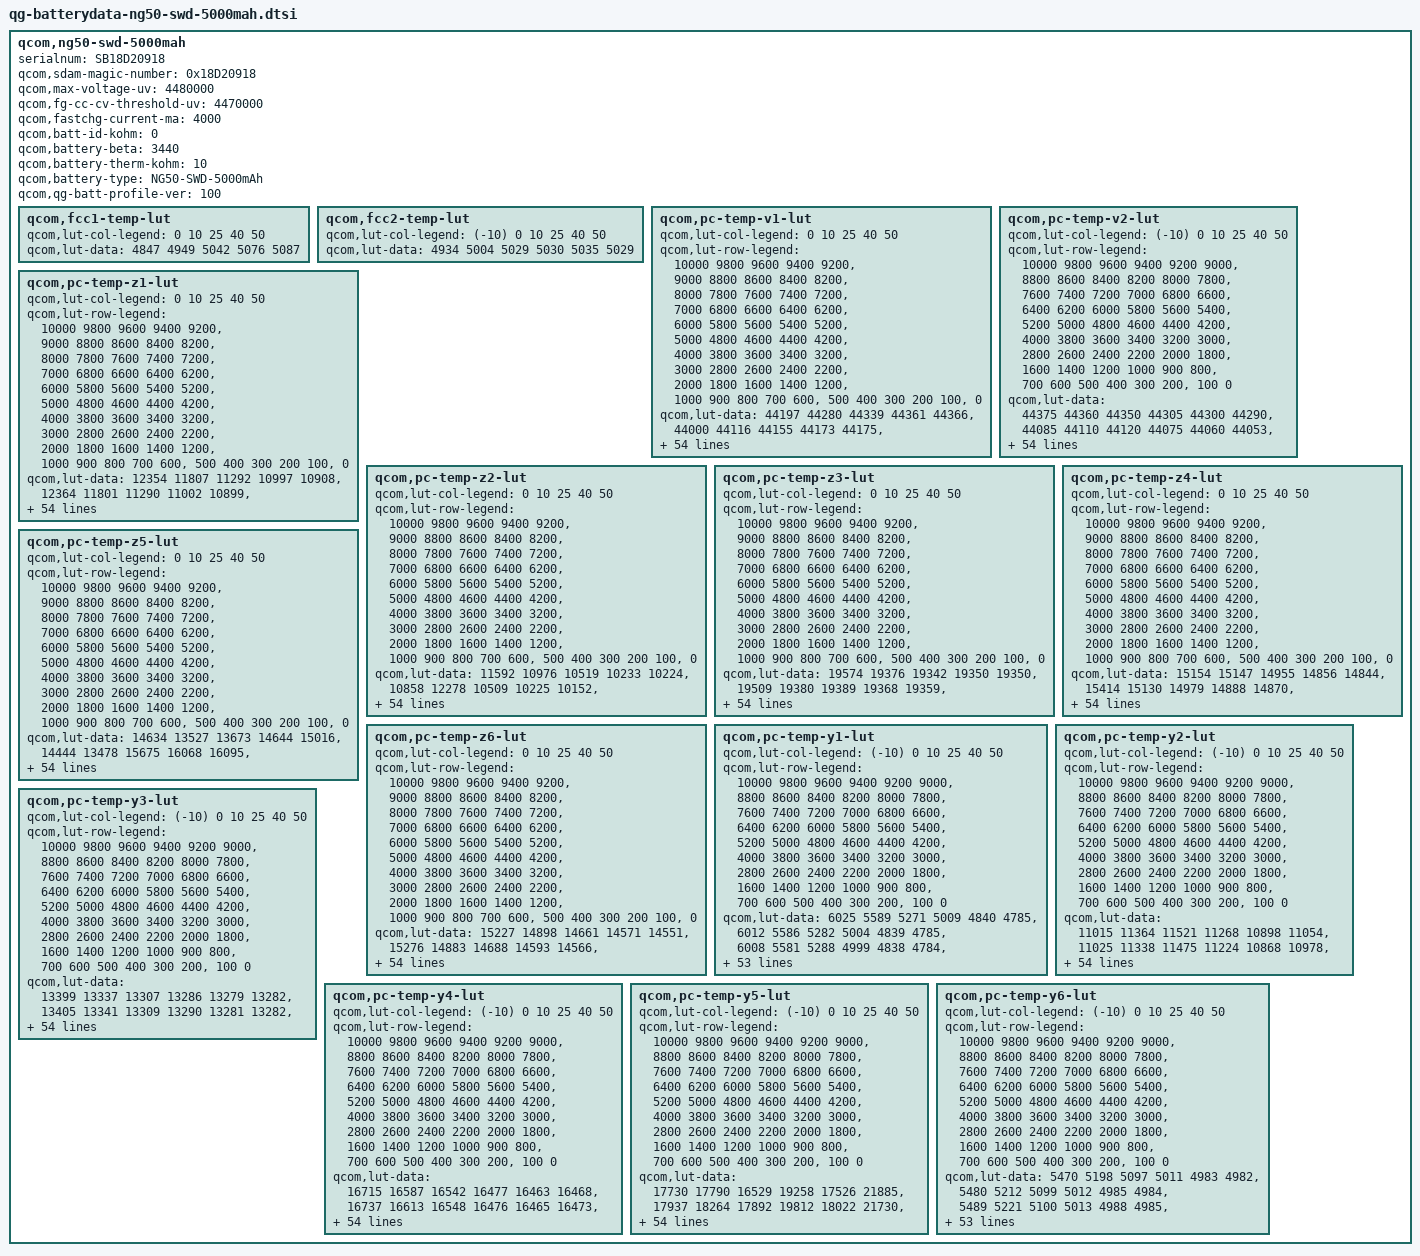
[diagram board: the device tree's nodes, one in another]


qcom,ng50-swd-5000mah {
    /* 5263913_Lenovo_Gorfu5G_Sunwoda_5000mAH_PM7250B_averaged_MasterSlave_Jul21th2021 */
    serialnum = "SB18D20918";
    qcom,sdam-magic-number = <0x18D20918>;
    qcom,max-voltage-uv = <4480000>;
    qcom,fg-cc-cv-threshold-uv = <4470000>;
    qcom,fastchg-current-ma = <4000>;
    qcom,batt-id-kohm = <0>;
    qcom,battery-beta = <3440>;
    qcom,battery-therm-kohm = <10>;
    qcom,battery-type = "NG50-SWD-5000mAh";
    qcom,qg-batt-profile-ver = <100>;

	qcom,fcc1-temp-lut {
		qcom,lut-col-legend = <0 10 25 40 50>;
		qcom,lut-data = <4847 4949 5042 5076 5087>;
	};

	qcom,fcc2-temp-lut {
		qcom,lut-col-legend = <(-10) 0 10 25 40 50>;
		qcom,lut-data = <4934 5004 5029 5030 5035 5029>;
	};

	qcom,pc-temp-v1-lut {
		qcom,lut-col-legend = <0 10 25 40 50>;
		qcom,lut-row-legend = <10000 9800 9600 9400 9200>,
			<9000 8800 8600 8400 8200>,
			<8000 7800 7600 7400 7200>,
			<7000 6800 6600 6400 6200>,
			<6000 5800 5600 5400 5200>,
			<5000 4800 4600 4400 4200>,
			<4000 3800 3600 3400 3200>,
			<3000 2800 2600 2400 2200>,
			<2000 1800 1600 1400 1200>,
			<1000 900 800 700 600>,
			<500 400 300 200 100>,
			<0>;
		qcom,lut-data = <44197 44280 44339 44361 44366>,
			<44000 44116 44155 44173 44175>,
			<43794 43931 43966 43983 43985>,
			<43581 43721 43770 43789 43792>,
			<43359 43491 43565 43585 43588>,
			<43127 43259 43351 43372 43374>,
			<42890 43025 43122 43148 43150>,
			<42650 42786 42880 42911 42917>,
			<42406 42544 42635 42668 42677>,
			<42168 42298 42392 42424 42435>,
			<41938 42058 42150 42178 42190>,
			<41714 41822 41909 41936 41949>,
			<41491 41592 41667 41696 41711>,
			<41270 41366 41432 41462 41477>,
			<41056 41147 41207 41237 41249>,
			<40851 40937 40990 41018 41025>,
			<40653 40738 40784 40805 40809>,
			<40460 40543 40588 40595 40602>,
			<40273 40356 40397 40396 40403>,
			<40083 40172 40218 40217 40219>,
			<39883 39949 40032 40041 40040>,
			<39675 39631 39792 39812 39820>,
			<39459 39336 39512 39513 39536>,
			<39211 39169 39290 39274 39293>,
			<39003 39050 39128 39133 39130>,
			<38888 38940 38992 39018 38998>,
			<38809 38835 38873 38895 38876>,
			<38732 38736 38768 38771 38764>,
			<38650 38640 38668 38660 38661>,
			<38573 38548 38570 38562 38562>,
			<38501 38464 38479 38475 38471>,
			<38432 38386 38399 38394 38389>,
			<38371 38315 38325 38319 38315>,
			<38320 38256 38258 38248 38242>,
			<38274 38205 38199 38182 38170>,
			<38234 38158 38142 38117 38097>,
			<38200 38118 38086 38051 38023>,
			<38159 38075 38030 37983 37945>,
			<38092 38008 37958 37899 37853>,
			<37997 37909 37860 37789 37734>,
			<37889 37795 37747 37664 37601>,
			<37756 37664 37623 37534 37465>,
			<37608 37518 37482 37395 37322>,
			<37437 37350 37318 37236 37157>,
			<37290 37207 37183 37115 37043>,
			<37201 37126 37098 37045 36985>,
			<37175 37097 37072 37017 36958>,
			<37150 37077 37055 36999 36936>,
			<37113 37049 37023 36964 36896>,
			<37048 36959 36913 36815 36717>,
			<36789 36622 36560 36458 36360>,
			<36329 36140 36079 35979 35883>,
			<35746 35509 35460 35360 35265>,
			<34943 34610 34609 34511 34415>,
			<33543 33152 33266 33165 33066>,
			<30000 30000 30000 30000 30000>;
	};

	qcom,pc-temp-v2-lut {
		qcom,lut-col-legend = <(-10) 0 10 25 40 50>;
		qcom,lut-row-legend = <10000 9800 9600 9400 9200 9000>,
			<8800 8600 8400 8200 8000 7800>,
			<7600 7400 7200 7000 6800 6600>,
			<6400 6200 6000 5800 5600 5400>,
			<5200 5000 4800 4600 4400 4200>,
			<4000 3800 3600 3400 3200 3000>,
			<2800 2600 2400 2200 2000 1800>,
			<1600 1400 1200 1000 900 800>,
			<700 600 500 400 300 200>,
			<100 0>;
		qcom,lut-data = <44375 44360 44350 44305 44300 44290>,
			<44085 44110 44120 44075 44060 44053>,
			<43818 43873 43896 43849 43830 43823>,
			<43575 43651 43681 43631 43611 43604>,
			<43359 43445 43476 43419 43403 43395>,
			<43143 43233 43262 43201 43190 43180>,
			<42912 42999 43029 42966 42960 42951>,
			<42675 42756 42786 42724 42722 42715>,
			<42436 42513 42542 42482 42481 42475>,
			<42191 42267 42296 42237 42234 42231>,
			<41951 42022 42050 41993 41989 41988>,
			<41723 41781 41808 41753 41750 41748>,
			<41502 41543 41568 41515 41514 41511>,
			<41280 41313 41334 41283 41282 41279>,
			<41062 41091 41105 41055 41056 41053>,
			<40837 40874 40883 40834 40836 40833>,
			<40595 40666 40671 40623 40623 40620>,
			<40339 40457 40462 40418 40417 40414>,
			<40081 40218 40245 40222 40225 40223>,
			<39813 39942 40023 40036 40045 40044>,
			<39558 39679 39789 39828 39844 39846>,
			<39339 39442 39525 39563 39588 39592>,
			<39144 39224 39267 39294 39328 39332>,
			<38959 39035 39068 39090 39123 39129>,
			<38779 38868 38903 38920 38949 38957>,
			<38611 38718 38756 38772 38797 38806>,
			<38452 38581 38624 38643 38665 38673>,
			<38302 38457 38504 38528 38548 38555>,
			<38188 38342 38395 38422 38442 38447>,
			<38108 38236 38295 38323 38346 38348>,
			<38044 38136 38201 38232 38259 38258>,
			<37984 38034 38111 38145 38181 38179>,
			<37931 37941 38028 38066 38105 38102>,
			<37876 37876 37952 37995 38027 38019>,
			<37817 37829 37881 37933 37948 37932>,
			<37757 37785 37816 37861 37859 37835>,
			<37693 37741 37757 37773 37754 37715>,
			<37629 37695 37696 37679 37646 37593>,
			<37558 37634 37622 37587 37550 37498>,
			<37473 37553 37535 37494 37460 37415>,
			<37379 37455 37434 37396 37362 37321>,
			<37280 37335 37314 37293 37258 37209>,
			<37174 37196 37182 37175 37135 37082>,
			<37064 37033 37037 37033 36988 36935>,
			<36952 36896 36911 36932 36897 36845>,
			<36847 36802 36847 36892 36868 36813>,
			<36798 36761 36822 36875 36853 36798>,
			<36742 36718 36791 36855 36832 36776>,
			<36678 36651 36733 36809 36782 36716>,
			<36609 36535 36593 36643 36584 36494>,
			<36510 36290 36243 36260 36182 36069>,
			<36335 35831 35674 35720 35644 35524>,
			<35964 35160 34945 35019 34942 34808>,
			<35302 34150 33931 34031 33966 33825>,
			<34253 32655 32434 32716 32626 32392>,
			<32930 29744 28050 28024 28024 28017>;
	};

	qcom,pc-temp-z1-lut {
		qcom,lut-col-legend = <0 10 25 40 50>;
		qcom,lut-row-legend = <10000 9800 9600 9400 9200>,
			<9000 8800 8600 8400 8200>,
			<8000 7800 7600 7400 7200>,
			<7000 6800 6600 6400 6200>,
			<6000 5800 5600 5400 5200>,
			<5000 4800 4600 4400 4200>,
			<4000 3800 3600 3400 3200>,
			<3000 2800 2600 2400 2200>,
			<2000 1800 1600 1400 1200>,
			<1000 900 800 700 600>,
			<500 400 300 200 100>,
			<0>;
		qcom,lut-data = <12354 11807 11292 10997 10908>,
			<12364 11801 11290 11002 10899>,
			<12358 11792 11276 10991 10894>,
			<12348 11776 11263 10979 10889>,
			<12334 11752 11250 10973 10885>,
			<12295 11737 11237 10969 10881>,
			<12260 11728 11227 10965 10878>,
			<12251 11718 11218 10960 10874>,
			<12246 11700 11210 10955 10871>,
			<12238 11678 11204 10952 10869>,
			<12214 11666 11199 10950 10867>,
			<12189 11660 11195 10947 10866>,
			<12178 11655 11191 10945 10866>,
			<12168 11652 11189 10943 10866>,
			<12161 11649 11186 10943 10865>,
			<12151 11648 11184 10943 10865>,
			<12139 11644 11184 10943 10865>,
			<12136 11641 11183 10943 10865>,
			<12136 11639 11183 10943 10866>,
			<12136 11639 11184 10943 10868>,
			<12140 11639 11186 10943 10869>,
			<12147 11640 11187 10944 10870>,
			<12148 11643 11188 10945 10870>,
			<12147 11648 11190 10947 10871>,
			<12146 11657 11195 10949 10873>,
			<12151 11662 11200 10952 10876>,
			<12162 11662 11205 10954 10879>,
			<12166 11662 11210 10957 10882>,
			<12167 11664 11214 10960 10885>,
			<12168 11669 11219 10964 10887>,
			<12169 11672 11224 10968 10889>,
			<12167 11673 11229 10972 10892>,
			<12166 11674 11234 10976 10896>,
			<12166 11679 11239 10980 10900>,
			<12169 11692 11245 10984 10903>,
			<12174 11699 11251 10988 10907>,
			<12181 11700 11257 10993 10911>,
			<12191 11701 11262 10998 10914>,
			<12207 11705 11269 11002 10918>,
			<12227 11718 11276 11007 10922>,
			<12236 11729 11284 11012 10926>,
			<12237 11738 11291 11016 10930>,
			<12241 11748 11297 11019 10932>,
			<12260 11758 11307 11022 10935>,
			<12283 11770 11318 11028 10938>,
			<12286 11785 11325 11031 10941>,
			<12291 11782 11326 11030 10941>,
			<12263 11778 11327 11030 10941>,
			<12270 11780 11331 11032 10944>,
			<12280 11788 11335 11037 10945>,
			<12291 11801 11343 11040 10949>,
			<12332 11812 11354 11047 10955>,
			<12348 11819 11365 11055 10962>,
			<12339 11839 11386 11066 10972>,
			<12339 11839 11386 11066 10972>,
			<12339 11839 11386 11066 10972>;
	};

	qcom,pc-temp-z2-lut {
		qcom,lut-col-legend = <0 10 25 40 50>;
		qcom,lut-row-legend = <10000 9800 9600 9400 9200>,
			<9000 8800 8600 8400 8200>,
			<8000 7800 7600 7400 7200>,
			<7000 6800 6600 6400 6200>,
			<6000 5800 5600 5400 5200>,
			<5000 4800 4600 4400 4200>,
			<4000 3800 3600 3400 3200>,
			<3000 2800 2600 2400 2200>,
			<2000 1800 1600 1400 1200>,
			<1000 900 800 700 600>,
			<500 400 300 200 100>,
			<0>;
		qcom,lut-data = <11592 10976 10519 10233 10224>,
			<10858 12278 10509 10225 10152>,
			<10782 12783 10529 10294 10203>,
			<10749 12149 10554 10365 10232>,
			<10713 11019 10770 10362 10260>,
			<10672 10694 11034 10338 10292>,
			<10639 10659 10956 10309 10302>,
			<10614 10635 10558 10268 10255>,
			<10594 10607 10349 10233 10202>,
			<10587 10581 10552 10218 10195>,
			<10656 10577 10816 10207 10202>,
			<10744 10597 10772 10207 10204>,
			<10741 10622 10499 10230 10200>,
			<10668 10635 10369 10249 10195>,
			<10629 10646 10373 10236 10188>,
			<10653 10694 10380 10212 10174>,
			<10687 10999 10599 10208 10170>,
			<10714 11267 11275 10224 10162>,
			<10740 11141 11634 10236 10154>,
			<10753 10814 11686 10225 10151>,
			<10743 10698 11736 10208 10149>,
			<10723 10714 12638 10229 10160>,
			<10717 10729 14925 10346 10221>,
			<10720 10717 15657 10414 10320>,
			<10723 10682 13114 10360 10689>,
			<10726 10670 10583 10287 11156>,
			<10729 10721 10483 10336 11151>,
			<10735 10775 10572 10561 10768>,
			<10749 10779 10609 10671 10456>,
			<10766 10776 10613 10549 10315>,
			<10778 10774 10613 10384 10214>,
			<10789 10770 10592 10316 10135>,
			<10798 10766 10549 10275 10069>,
			<10808 10770 10534 10245 10043>,
			<10818 10784 10536 10214 10049>,
			<10829 10798 10542 10194 10068>,
			<10840 10810 10571 10208 10102>,
			<10854 10823 10628 10257 10168>,
			<10876 10846 10671 10324 10240>,
			<10902 10886 10703 10456 10332>,
			<10914 10908 10728 10566 10420>,
			<10916 10911 10751 10596 10482>,
			<10923 10915 10765 10610 10528>,
			<10978 10945 10754 10592 10538>,
			<11293 11123 10774 10535 10457>,
			<11357 11206 10804 10415 10291>,
			<11188 11199 10782 10382 10276>,
			<10972 11226 10710 10385 10301>,
			<10860 11275 10777 10478 10360>,
			<10818 11453 10788 10435 10336>,
			<10734 11344 10769 10276 10155>,
			<10601 11293 10635 10133 10040>,
			<10397 11134 10508 10066 9946>,
			<10223 10902 10457 9988 9911>,
			<10223 10902 10457 9988 9911>,
			<10223 10902 10457 9988 9911>;
	};

	qcom,pc-temp-z3-lut {
		qcom,lut-col-legend = <0 10 25 40 50>;
		qcom,lut-row-legend = <10000 9800 9600 9400 9200>,
			<9000 8800 8600 8400 8200>,
			<8000 7800 7600 7400 7200>,
			<7000 6800 6600 6400 6200>,
			<6000 5800 5600 5400 5200>,
			<5000 4800 4600 4400 4200>,
			<4000 3800 3600 3400 3200>,
			<3000 2800 2600 2400 2200>,
			<2000 1800 1600 1400 1200>,
			<1000 900 800 700 600>,
			<500 400 300 200 100>,
			<0>;
		qcom,lut-data = <19574 19376 19342 19350 19350>,
			<19509 19380 19389 19368 19359>,
			<19535 19391 19414 19387 19378>,
			<19584 19434 19433 19404 19391>,
			<19610 19499 19452 19415 19403>,
			<19621 19517 19467 19423 19413>,
			<19630 19520 19468 19429 19419>,
			<19638 19521 19465 19433 19422>,
			<19645 19521 19462 19436 19424>,
			<19649 19521 19467 19434 19423>,
			<19652 19520 19474 19430 19418>,
			<19654 19512 19470 19426 19414>,
			<19650 19503 19454 19422 19410>,
			<19635 19497 19443 19419 19406>,
			<19622 19492 19436 19413 19403>,
			<19613 19492 19431 19406 19399>,
			<19607 19509 19435 19402 19395>,
			<19601 19525 19446 19399 19390>,
			<19595 19514 19451 19396 19386>,
			<19592 19487 19448 19390 19382>,
			<19601 19479 19442 19383 19378>,
			<19618 19504 19433 19382 19374>,
			<19630 19529 19417 19383 19371>,
			<19637 19519 19405 19383 19369>,
			<19641 19491 19395 19375 19398>,
			<19634 19476 19389 19363 19441>,
			<19616 19473 19391 19375 19448>,
			<19607 19472 19396 19424 19445>,
			<19605 19476 19405 19448 19441>,
			<19604 19488 19424 19443 19435>,
			<19604 19496 19440 19435 19425>,
			<19605 19498 19441 19427 19416>,
			<19605 19500 19440 19418 19406>,
			<19603 19499 19437 19409 19395>,
			<19598 19494 19430 19396 19383>,
			<19595 19490 19422 19385 19373>,
			<19593 19486 19416 19376 19366>,
			<19590 19482 19411 19369 19361>,
			<19585 19477 19406 19366 19358>,
			<19577 19472 19403 19366 19355>,
			<19570 19468 19401 19366 19353>,
			<19563 19465 19399 19372 19361>,
			<19553 19460 19398 19383 19376>,
			<19534 19451 19395 19384 19380>,
			<19475 19427 19382 19380 19378>,
			<19424 19401 19370 19355 19358>,
			<19362 19399 19368 19350 19347>,
			<19303 19385 19360 19339 19337>,
			<19299 19354 19356 19332 19330>,
			<19296 19315 19346 19349 19342>,
			<19300 19333 19372 19373 19365>,
			<19301 19316 19383 19375 19363>,
			<19302 19316 19378 19375 19364>,
			<19318 19422 19383 19376 19365>,
			<19318 19422 19383 19376 19365>,
			<19318 19422 19383 19376 19365>;
	};

	qcom,pc-temp-z4-lut {
		qcom,lut-col-legend = <0 10 25 40 50>;
		qcom,lut-row-legend = <10000 9800 9600 9400 9200>,
			<9000 8800 8600 8400 8200>,
			<8000 7800 7600 7400 7200>,
			<7000 6800 6600 6400 6200>,
			<6000 5800 5600 5400 5200>,
			<5000 4800 4600 4400 4200>,
			<4000 3800 3600 3400 3200>,
			<3000 2800 2600 2400 2200>,
			<2000 1800 1600 1400 1200>,
			<1000 900 800 700 600>,
			<500 400 300 200 100>,
			<0>;
		qcom,lut-data = <15154 15147 14955 14856 14844>,
			<15414 15130 14979 14888 14870>,
			<15374 15102 14956 14880 14866>,
			<15278 15056 14926 14865 14857>,
			<15195 14996 14877 14846 14843>,
			<15119 14947 14826 14819 14819>,
			<15052 14907 14805 14795 14797>,
			<14999 14871 14794 14775 14778>,
			<14955 14841 14779 14758 14762>,
			<14915 14814 14741 14743 14750>,
			<14872 14792 14703 14731 14741>,
			<14837 14772 14698 14723 14735>,
			<14826 14759 14710 14719 14732>,
			<14824 14754 14715 14716 14730>,
			<14820 14751 14712 14713 14727>,
			<14807 14743 14707 14711 14725>,
			<14794 14710 14691 14708 14723>,
			<14792 14681 14659 14705 14721>,
			<14795 14688 14645 14701 14718>,
			<14797 14713 14644 14698 14714>,
			<14794 14744 14643 14695 14709>,
			<14790 14789 14671 14711 14720>,
			<14793 14830 14755 14788 14792>,
			<14835 14848 14810 14834 14839>,
			<14874 14860 14838 14834 14802>,
			<14875 14863 14853 14833 14743>,
			<14867 14852 14847 14815 14723>,
			<14858 14835 14826 14750 14715>,
			<14845 14815 14802 14713 14710>,
			<14831 14790 14770 14707 14707>,
			<14822 14773 14742 14704 14704>,
			<14816 14762 14729 14699 14701>,
			<14812 14756 14719 14694 14696>,
			<14811 14756 14716 14692 14692>,
			<14810 14757 14714 14691 14689>,
			<14808 14758 14714 14691 14686>,
			<14806 14756 14714 14690 14684>,
			<14803 14754 14715 14689 14682>,
			<14798 14753 14717 14690 14683>,
			<14792 14753 14726 14703 14700>,
			<14783 14753 14733 14715 14716>,
			<14768 14743 14729 14709 14710>,
			<14750 14727 14723 14700 14699>,
			<14730 14716 14720 14702 14703>,
			<14694 14684 14704 14692 14694>,
			<14711 14669 14678 14677 14665>,
			<14771 14662 14670 14673 14664>,
			<14831 14663 14658 14663 14652>,
			<14833 14690 14646 14643 14632>,
			<14829 14732 14660 14641 14650>,
			<14827 14726 14668 14667 14679>,
			<14835 14750 14664 14677 14693>,
			<14838 14755 14671 14682 14701>,
			<14840 14661 14668 14686 14703>,
			<14840 14661 14668 14686 14703>,
			<14840 14661 14668 14686 14703>;
	};

	qcom,pc-temp-z5-lut {
		qcom,lut-col-legend = <0 10 25 40 50>;
		qcom,lut-row-legend = <10000 9800 9600 9400 9200>,
			<9000 8800 8600 8400 8200>,
			<8000 7800 7600 7400 7200>,
			<7000 6800 6600 6400 6200>,
			<6000 5800 5600 5400 5200>,
			<5000 4800 4600 4400 4200>,
			<4000 3800 3600 3400 3200>,
			<3000 2800 2600 2400 2200>,
			<2000 1800 1600 1400 1200>,
			<1000 900 800 700 600>,
			<500 400 300 200 100>,
			<0>;
		qcom,lut-data = <14634 13527 13673 14644 15016>,
			<14444 13478 15675 16068 16095>,
			<15077 13470 16792 17667 17797>,
			<16027 14846 17791 19187 19231>,
			<16759 17392 18966 20276 20839>,
			<17269 18447 20000 21161 22516>,
			<17812 18769 20501 22176 23961>,
			<18584 19096 20764 23426 25177>,
			<19523 19723 21250 24703 26254>,
			<20464 20536 25047 25921 27270>,
			<21647 21270 29617 27108 28224>,
			<22698 22019 29697 28077 28735>,
			<23035 22547 27010 29017 28983>,
			<23094 22700 25661 29528 29192>,
			<23317 22790 25829 29309 29599>,
			<24520 23459 26336 28889 30312>,
			<25965 28931 29235 29123 30937>,
			<26124 33888 36477 31274 31578>,
			<25536 31796 40011 32760 32271>,
			<25126 26207 40581 32448 33164>,
			<27655 25048 40854 31701 34020>,
			<33221 37281 38784 30676 33313>,
			<37332 49235 32145 28656 28025>,
			<40639 44787 26551 26049 24539>,
			<42618 30862 21922 21549 27731>,
			<40199 24081 18941 17291 32854>,
			<33603 22655 18613 18975 34605>,
			<30778 21955 18493 27450 35404>,
			<31112 22619 18672 32235 35697>,
			<31786 25166 21545 32820 35843>,
			<32973 27916 25125 33008 36006>,
			<35289 31180 27530 33082 35650>,
			<36914 33932 29778 33181 34279>,
			<37506 34768 30941 32829 32833>,
			<37922 35225 31603 30652 30824>,
			<38078 35364 31927 28342 29143>,
			<38139 34905 31833 27609 28953>,
			<38156 34217 31515 27184 29023>,
			<38191 33798 30978 26961 28817>,
			<38296 33426 29593 26816 26788>,
			<38447 33276 28060 26743 24955>,
			<38920 33681 26778 27578 26785>,
			<39365 34127 25860 29132 31034>,
			<39695 33321 25620 29820 34233>,
			<38595 36064 25485 29355 34210>,
			<26098 31230 25903 21516 24852>,
			<18752 30714 25876 20258 20360>,
			<13181 24707 25518 19304 19784>,
			<12996 19827 28262 22158 24505>,
			<12922 14452 21701 36030 38896>,
			<13103 15670 23035 25093 24002>,
			<12919 14015 23747 21452 19000>,
			<12789 14200 20877 18985 16805>,
			<13428 35346 20533 16947 15037>,
			<13428 35346 20533 16947 15037>,
			<13428 35346 20533 16947 15037>;
	};

	qcom,pc-temp-z6-lut {
		qcom,lut-col-legend = <0 10 25 40 50>;
		qcom,lut-row-legend = <10000 9800 9600 9400 9200>,
			<9000 8800 8600 8400 8200>,
			<8000 7800 7600 7400 7200>,
			<7000 6800 6600 6400 6200>,
			<6000 5800 5600 5400 5200>,
			<5000 4800 4600 4400 4200>,
			<4000 3800 3600 3400 3200>,
			<3000 2800 2600 2400 2200>,
			<2000 1800 1600 1400 1200>,
			<1000 900 800 700 600>,
			<500 400 300 200 100>,
			<0>;
		qcom,lut-data = <15227 14898 14661 14571 14551>,
			<15276 14883 14688 14593 14566>,
			<15262 14872 14689 14599 14574>,
			<15227 14866 14689 14601 14577>,
			<15192 14861 14679 14599 14576>,
			<15151 14852 14663 14591 14572>,
			<15112 14830 14651 14583 14567>,
			<15083 14807 14642 14577 14561>,
			<15058 14789 14632 14571 14555>,
			<15035 14773 14619 14563 14549>,
			<15012 14757 14607 14555 14542>,
			<14992 14742 14600 14549 14537>,
			<14976 14730 14595 14546 14533>,
			<14963 14723 14591 14542 14530>,
			<14951 14719 14586 14537 14527>,
			<14936 14715 14581 14532 14523>,
			<14923 14710 14575 14528 14519>,
			<14920 14707 14570 14525 14516>,
			<14919 14704 14566 14521 14512>,
			<14919 14703 14563 14516 14507>,
			<14922 14705 14561 14511 14503>,
			<14929 14739 14572 14518 14507>,
			<14940 14772 14605 14552 14536>,
			<14965 14772 14620 14571 14555>,
			<14984 14766 14622 14568 14554>,
			<14982 14761 14623 14562 14552>,
			<14971 14754 14622 14560 14550>,
			<14962 14748 14616 14558 14545>,
			<14957 14744 14612 14557 14540>,
			<14952 14741 14609 14552 14536>,
			<14950 14738 14606 14547 14531>,
			<14948 14736 14603 14542 14526>,
			<14947 14734 14599 14536 14519>,
			<14946 14734 14595 14530 14512>,
			<14945 14734 14592 14524 14504>,
			<14946 14734 14589 14518 14498>,
			<14947 14732 14586 14513 14493>,
			<14949 14731 14584 14509 14489>,
			<14948 14731 14584 14508 14488>,
			<14948 14732 14588 14513 14492>,
			<14947 14733 14590 14518 14498>,
			<14943 14729 14589 14520 14502>,
			<14938 14723 14587 14522 14504>,
			<14929 14718 14586 14523 14509>,
			<14896 14699 14575 14518 14504>,
			<14887 14683 14558 14499 14482>,
			<14880 14679 14554 14494 14476>,
			<14877 14673 14545 14485 14466>,
			<14880 14673 14539 14472 14452>,
			<14880 14673 14541 14480 14466>,
			<14892 14687 14561 14506 14493>,
			<14903 14693 14567 14514 14502>,
			<14912 14701 14570 14519 14508>,
			<14937 14727 14577 14524 14514>,
			<14937 14727 14577 14524 14514>,
			<14937 14727 14577 14524 14514>;
	};

	qcom,pc-temp-y1-lut {
		qcom,lut-col-legend = <(-10) 0 10 25 40 50>;
		qcom,lut-row-legend = <10000 9800 9600 9400 9200 9000>,
			<8800 8600 8400 8200 8000 7800>,
			<7600 7400 7200 7000 6800 6600>,
			<6400 6200 6000 5800 5600 5400>,
			<5200 5000 4800 4600 4400 4200>,
			<4000 3800 3600 3400 3200 3000>,
			<2800 2600 2400 2200 2000 1800>,
			<1600 1400 1200 1000 900 800>,
			<700 600 500 400 300 200>,
			<100 0>;
		qcom,lut-data = <6025 5589 5271 5009 4840 4785>,
			<6012 5586 5282 5004 4839 4785>,
			<6008 5581 5288 4999 4838 4784>,
			<6011 5575 5291 4994 4836 4784>,
			<6015 5570 5290 4990 4835 4783>,
			<6017 5568 5289 4987 4834 4783>,
			<6021 5566 5284 4984 4832 4783>,
			<6028 5563 5277 4981 4831 4783>,
			<6029 5562 5271 4978 4830 4782>,
			<6021 5562 5265 4975 4828 4781>,
			<6015 5562 5261 4972 4827 4780>,
			<6019 5565 5259 4970 4826 4779>,
			<6026 5571 5258 4969 4825 4778>,
			<6029 5571 5257 4968 4824 4778>,
			<6029 5567 5255 4968 4824 4779>,
			<6029 5563 5253 4968 4824 4779>,
			<6027 5558 5252 4969 4825 4780>,
			<6021 5554 5250 4969 4826 4780>,
			<6022 5554 5251 4970 4826 4781>,
			<6026 5558 5253 4970 4826 4782>,
			<6029 5563 5254 4971 4827 4782>,
			<6033 5570 5257 4973 4828 4782>,
			<6042 5576 5260 4976 4830 4783>,
			<6046 5577 5261 4980 4832 4784>,
			<6043 5574 5262 4983 4834 4787>,
			<6039 5572 5263 4987 4837 4789>,
			<6039 5575 5267 4990 4839 4790>,
			<6039 5581 5272 4994 4841 4792>,
			<6039 5582 5275 4997 4843 4793>,
			<6044 5580 5278 5000 4844 4795>,
			<6051 5579 5280 5004 4846 4798>,
			<6048 5586 5285 5007 4849 4801>,
			<6040 5594 5289 5012 4852 4804>,
			<6037 5596 5292 5016 4855 4805>,
			<6039 5594 5294 5020 4857 4806>,
			<6043 5593 5297 5025 4859 4807>,
			<6041 5601 5300 5029 4861 4809>,
			<6030 5610 5304 5033 4863 4810>,
			<6023 5609 5307 5036 4865 4812>,
			<6026 5596 5311 5038 4866 4813>,
			<6030 5589 5313 5041 4868 4815>,
			<6030 5598 5322 5044 4869 4816>,
			<6024 5606 5326 5048 4871 4818>,
			<6015 5598 5331 5055 4875 4819>,
			<6000 5602 5341 5061 4879 4823>,
			<6037 5604 5339 5063 4878 4824>,
			<6038 5622 5344 5066 4878 4824>,
			<6067 5621 5347 5063 4878 4824>,
			<6046 5616 5354 5062 4879 4825>,
			<6036 5631 5357 5061 4880 4827>,
			<6069 5633 5369 5064 4882 4830>,
			<6117 5664 5368 5073 4886 4832>,
			<6191 5734 5383 5086 4891 4837>,
			<6270 5778 5448 5102 4898 4846>,
			<6270 5778 5448 5102 4898 4846>,
			<6270 5778 5448 5102 4898 4846>;
	};

	qcom,pc-temp-y2-lut {
		qcom,lut-col-legend = <(-10) 0 10 25 40 50>;
		qcom,lut-row-legend = <10000 9800 9600 9400 9200 9000>,
			<8800 8600 8400 8200 8000 7800>,
			<7600 7400 7200 7000 6800 6600>,
			<6400 6200 6000 5800 5600 5400>,
			<5200 5000 4800 4600 4400 4200>,
			<4000 3800 3600 3400 3200 3000>,
			<2800 2600 2400 2200 2000 1800>,
			<1600 1400 1200 1000 900 800>,
			<700 600 500 400 300 200>,
			<100 0>;
		qcom,lut-data = <11015 11364 11521 11268 10898 11054>,
			<11025 11338 11475 11224 10868 10978>,
			<11033 11313 11430 11180 10834 10888>,
			<11040 11288 11386 11134 10800 10800>,
			<11045 11263 11344 11088 10770 10731>,
			<11047 11238 11303 11042 10747 10696>,
			<11047 11209 11258 10983 10731 10694>,
			<11045 11182 11218 10932 10717 10697>,
			<11045 11168 11198 10930 10700 10689>,
			<11043 11159 11184 10951 10677 10669>,
			<11043 11156 11178 10963 10663 10649>,
			<11052 11165 11183 10954 10667 10630>,
			<11069 11184 11194 10943 10678 10614>,
			<11099 11203 11214 10944 10687 10611>,
			<11177 11225 11255 10960 10706 10617>,
			<11248 11254 11300 10979 10720 10621>,
			<11266 11322 11337 11006 10725 10621>,
			<11275 11405 11377 11048 10729 10626>,
			<11288 11444 11436 11132 10777 10659>,
			<11312 11464 11518 11287 10923 10761>,
			<11330 11480 11552 11358 11015 10829>,
			<11329 11495 11530 11326 11044 10870>,
			<11321 11509 11503 11285 11061 10906>,
			<11302 11523 11506 11281 11057 10911>,
			<10992 11540 11531 11296 11039 10911>,
			<10640 11550 11556 11317 11032 10913>,
			<10713 11553 11579 11354 11056 10932>,
			<11089 11555 11602 11394 11098 10965>,
			<11281 11552 11631 11416 11161 11005>,
			<11275 11542 11668 11436 11263 11063>,
			<11255 11536 11685 11451 11332 11132>,
			<11044 11550 11687 11496 11373 11229>,
			<10321 11569 11688 11554 11414 11324>,
			<9864 11555 11684 11608 11472 11386>,
			<9783 11463 11677 11673 11543 11436>,
			<9736 11367 11665 11691 11564 11447>,
			<9712 11304 11637 11606 11509 11347>,
			<9697 11243 11596 11512 11426 11240>,
			<9688 11174 11544 11493 11333 11244>,
			<9682 11095 11471 11485 11224 11275>,
			<9679 11006 11388 11480 11194 11281>,
			<9675 10919 11289 11490 11230 11177>,
			<9672 10775 11191 11477 11223 11046>,
			<9670 10091 11102 11352 11013 10913>,
			<9667 9806 10957 11245 10896 10767>,
			<9665 9740 10939 11204 10844 10718>,
			<9664 9716 10901 11197 10849 10720>,
			<9663 9693 10867 11206 10918 10766>,
			<9661 9684 10802 11232 10942 10781>,
			<9658 9672 10703 11227 10843 10734>,
			<9654 9663 10537 11171 10764 10690>,
			<9650 9654 10036 11057 10699 10606>,
			<9649 9651 9696 10914 10583 10474>,
			<9648 9652 9672 10762 10431 10293>,
			<9648 9652 9672 10762 10431 10293>,
			<9648 9652 9672 10762 10431 10293>;
	};

	qcom,pc-temp-y3-lut {
		qcom,lut-col-legend = <(-10) 0 10 25 40 50>;
		qcom,lut-row-legend = <10000 9800 9600 9400 9200 9000>,
			<8800 8600 8400 8200 8000 7800>,
			<7600 7400 7200 7000 6800 6600>,
			<6400 6200 6000 5800 5600 5400>,
			<5200 5000 4800 4600 4400 4200>,
			<4000 3800 3600 3400 3200 3000>,
			<2800 2600 2400 2200 2000 1800>,
			<1600 1400 1200 1000 900 800>,
			<700 600 500 400 300 200>,
			<100 0>;
		qcom,lut-data = <13399 13337 13307 13286 13279 13282>,
			<13405 13341 13309 13290 13281 13282>,
			<13411 13345 13312 13292 13283 13283>,
			<13417 13350 13316 13294 13285 13284>,
			<13422 13353 13319 13295 13286 13284>,
			<13426 13356 13320 13295 13288 13285>,
			<13429 13357 13319 13295 13289 13286>,
			<13430 13357 13319 13294 13290 13287>,
			<13431 13358 13319 13295 13291 13288>,
			<13429 13360 13320 13297 13291 13289>,
			<13428 13360 13321 13299 13291 13289>,
			<13431 13359 13321 13299 13292 13290>,
			<13438 13357 13321 13300 13293 13291>,
			<13439 13356 13321 13300 13294 13291>,
			<13432 13356 13321 13300 13295 13292>,
			<13421 13355 13320 13300 13295 13292>,
			<13414 13357 13320 13302 13295 13293>,
			<13406 13358 13320 13305 13295 13293>,
			<13400 13357 13321 13305 13296 13294>,
			<13395 13350 13322 13303 13299 13296>,
			<13390 13343 13322 13302 13299 13297>,
			<13385 13338 13317 13298 13295 13292>,
			<13380 13335 13310 13294 13288 13285>,
			<13374 13332 13306 13292 13287 13284>,
			<13363 13329 13304 13291 13286 13284>,
			<13351 13327 13302 13289 13285 13284>,
			<13343 13326 13302 13288 13284 13284>,
			<13332 13325 13302 13287 13282 13284>,
			<13326 13324 13302 13287 13283 13284>,
			<13324 13323 13302 13287 13283 13284>,
			<13324 13322 13302 13287 13283 13284>,
			<13327 13316 13302 13286 13283 13284>,
			<13333 13307 13301 13285 13283 13283>,
			<13342 13307 13301 13286 13284 13284>,
			<13353 13312 13301 13287 13285 13286>,
			<13368 13318 13302 13287 13286 13286>,
			<13386 13324 13302 13287 13284 13284>,
			<13408 13329 13302 13286 13283 13282>,
			<13432 13333 13303 13286 13283 13283>,
			<13457 13336 13304 13286 13285 13286>,
			<13484 13339 13305 13286 13285 13287>,
			<13519 13341 13306 13289 13285 13285>,
			<13566 13343 13307 13290 13285 13283>,
			<13622 13345 13309 13287 13282 13282>,
			<13694 13355 13310 13290 13284 13284>,
			<13797 13376 13313 13295 13292 13289>,
			<13831 13395 13318 13298 13294 13292>,
			<13914 13429 13325 13303 13296 13294>,
			<14047 13478 13333 13305 13296 13293>,
			<14269 13565 13342 13301 13291 13290>,
			<14807 13771 13351 13299 13290 13291>,
			<16653 14733 13378 13301 13293 13294>,
			<22477 19524 13594 13307 13298 13299>,
			<43551 40940 15967 13316 13309 13309>,
			<43551 40940 15967 13316 13309 13309>,
			<43551 40940 15967 13316 13309 13309>;
	};

	qcom,pc-temp-y4-lut {
		qcom,lut-col-legend = <(-10) 0 10 25 40 50>;
		qcom,lut-row-legend = <10000 9800 9600 9400 9200 9000>,
			<8800 8600 8400 8200 8000 7800>,
			<7600 7400 7200 7000 6800 6600>,
			<6400 6200 6000 5800 5600 5400>,
			<5200 5000 4800 4600 4400 4200>,
			<4000 3800 3600 3400 3200 3000>,
			<2800 2600 2400 2200 2000 1800>,
			<1600 1400 1200 1000 900 800>,
			<700 600 500 400 300 200>,
			<100 0>;
		qcom,lut-data = <16715 16587 16542 16477 16463 16468>,
			<16737 16613 16548 16476 16465 16473>,
			<16784 16639 16552 16476 16468 16478>,
			<16839 16662 16555 16476 16471 16482>,
			<16886 16679 16557 16477 16473 16485>,
			<16907 16685 16557 16479 16474 16485>,
			<16906 16679 16555 16482 16474 16484>,
			<16904 16671 16553 16486 16474 16483>,
			<16904 16669 16552 16487 16474 16482>,
			<16906 16668 16552 16487 16475 16481>,
			<16908 16668 16553 16488 16477 16481>,
			<16910 16676 16558 16492 16478 16482>,
			<16914 16692 16569 16499 16481 16482>,
			<16923 16709 16580 16506 16484 16484>,
			<16960 16731 16594 16514 16488 16486>,
			<16991 16752 16612 16524 16493 16490>,
			<16982 16775 16643 16535 16499 16494>,
			<16950 16794 16672 16548 16508 16500>,
			<16910 16788 16674 16570 16524 16512>,
			<16843 16739 16667 16605 16548 16531>,
			<16779 16686 16655 16620 16558 16540>,
			<16744 16646 16604 16575 16538 16526>,
			<16719 16612 16543 16515 16508 16503>,
			<16703 16593 16526 16493 16491 16490>,
			<16695 16582 16517 16480 16476 16479>,
			<16689 16573 16515 16477 16471 16474>,
			<16671 16567 16515 16480 16473 16473>,
			<16631 16562 16515 16486 16476 16472>,
			<16612 16555 16517 16492 16480 16474>,
			<16614 16545 16520 16499 16487 16479>,
			<16618 16537 16522 16506 16495 16486>,
			<16627 16533 16524 16513 16507 16498>,
			<16649 16529 16525 16521 16517 16509>,
			<16668 16530 16524 16528 16519 16514>,
			<16681 16535 16520 16535 16520 16518>,
			<16691 16544 16518 16537 16520 16518>,
			<16697 16560 16522 16522 16507 16505>,
			<16702 16578 16527 16505 16494 16491>,
			<16705 16587 16528 16498 16495 16494>,
			<16709 16593 16529 16493 16497 16508>,
			<16711 16595 16529 16492 16500 16516>,
			<16711 16586 16530 16496 16505 16518>,
			<16707 16579 16530 16497 16502 16514>,
			<16708 16596 16528 16479 16463 16465>,
			<16719 16610 16530 16477 16462 16468>,
			<16737 16614 16532 16489 16502 16525>,
			<16717 16632 16551 16513 16538 16563>,
			<16728 16662 16577 16546 16573 16599>,
			<16753 16700 16619 16579 16595 16607>,
			<16778 16754 16638 16555 16542 16547>,
			<16833 16794 16625 16504 16493 16493>,
			<17215 16877 16651 16500 16488 16491>,
			<18926 19221 16772 16512 16487 16489>,
			<34174 47726 18257 16542 16504 16510>,
			<34174 47726 18257 16542 16504 16510>,
			<34174 47726 18257 16542 16504 16510>;
	};

	qcom,pc-temp-y5-lut {
		qcom,lut-col-legend = <(-10) 0 10 25 40 50>;
		qcom,lut-row-legend = <10000 9800 9600 9400 9200 9000>,
			<8800 8600 8400 8200 8000 7800>,
			<7600 7400 7200 7000 6800 6600>,
			<6400 6200 6000 5800 5600 5400>,
			<5200 5000 4800 4600 4400 4200>,
			<4000 3800 3600 3400 3200 3000>,
			<2800 2600 2400 2200 2000 1800>,
			<1600 1400 1200 1000 900 800>,
			<700 600 500 400 300 200>,
			<100 0>;
		qcom,lut-data = <17730 17790 16529 19258 17526 21885>,
			<17937 18264 17892 19812 18022 21730>,
			<18162 18628 18670 19905 18735 21461>,
			<18380 18881 19002 19657 19478 21146>,
			<18565 19020 19026 19187 20063 20855>,
			<18694 19043 18880 18613 20300 20656>,
			<18780 18859 18311 17540 20283 20474>,
			<18841 18519 17506 16366 20206 20313>,
			<18801 18213 17084 16138 19867 20214>,
			<18401 17919 16844 16459 18772 19866>,
			<18077 17561 16577 16553 18073 19655>,
			<18516 16895 16045 16204 17811 19266>,
			<19431 16204 15457 15730 17479 18647>,
			<19682 16055 15134 15247 17206 18262>,
			<19367 16099 14847 14697 16915 17726>,
			<19085 16229 14729 14407 16542 17183>,
			<19577 17393 14974 14453 15822 16574>,
			<20892 19331 15539 14663 15163 16019>,
			<21777 20647 17098 15025 15150 15824>,
			<22313 21749 20831 15758 15450 15875>,
			<22636 22280 22635 16780 15951 16115>,
			<22693 22264 22105 19115 17795 17169>,
			<22720 22162 21281 21352 19902 18590>,
			<22669 22080 20670 21420 20610 19637>,
			<20909 21973 20035 20728 21006 20791>,
			<18835 21919 19789 19973 21060 21231>,
			<17806 22095 19901 19018 19094 20152>,
			<15543 22478 20132 18159 16867 18628>,
			<14209 23073 20564 17920 16565 17824>,
			<13832 24307 21389 17963 16489 17222>,
			<13613 24964 22120 18002 16475 16908>,
			<13498 21721 22652 17776 16608 16744>,
			<13336 17001 23181 17617 16882 16650>,
			<13255 16423 23923 18301 17700 17391>,
			<13272 17626 24824 20016 19338 19630>,
			<13313 18846 25106 21134 20188 20560>,
			<13454 20243 24202 21713 20375 20257>,
			<13869 21721 22931 22038 20465 19935>,
			<14108 22163 22107 21590 20871 20755>,
			<13982 22223 21412 20333 21678 23106>,
			<13794 22188 20794 19937 22034 23998>,
			<13772 21749 20202 21156 22221 23362>,
			<13838 20892 19788 21582 22017 22477>,
			<13761 16184 19292 19869 19659 21335>,
			<13419 14365 18278 19344 17555 17972>,
			<13369 14021 18450 18877 17437 15355>,
			<13661 13977 18514 18609 16346 14812>,
			<13650 14278 18512 18617 15913 14667>,
			<13523 14506 18367 18505 15727 14487>,
			<13983 14414 18308 18014 15189 14881>,
			<13751 14152 17957 18928 16066 16062>,
			<11774 13280 15359 19555 16497 15802>,
			<9834 9862 13524 19881 17052 16248>,
			<8966 8906 10883 22632 24676 23548>,
			<8966 8906 10883 22632 24676 23548>,
			<8966 8906 10883 22632 24676 23548>;
	};

	qcom,pc-temp-y6-lut {
		qcom,lut-col-legend = <(-10) 0 10 25 40 50>;
		qcom,lut-row-legend = <10000 9800 9600 9400 9200 9000>,
			<8800 8600 8400 8200 8000 7800>,
			<7600 7400 7200 7000 6800 6600>,
			<6400 6200 6000 5800 5600 5400>,
			<5200 5000 4800 4600 4400 4200>,
			<4000 3800 3600 3400 3200 3000>,
			<2800 2600 2400 2200 2000 1800>,
			<1600 1400 1200 1000 900 800>,
			<700 600 500 400 300 200>,
			<100 0>;
		qcom,lut-data = <5470 5198 5097 5011 4983 4982>,
			<5480 5212 5099 5012 4985 4984>,
			<5489 5221 5100 5013 4988 4985>,
			<5498 5227 5100 5014 4990 4987>,
			<5504 5230 5100 5015 4992 4989>,
			<5507 5231 5100 5015 4993 4990>,
			<5505 5228 5098 5015 4994 4990>,
			<5503 5222 5095 5015 4994 4990>,
			<5499 5220 5094 5016 4995 4991>,
			<5494 5219 5093 5017 4995 4991>,
			<5491 5218 5093 5019 4995 4992>,
			<5493 5219 5093 5020 4997 4992>,
			<5497 5220 5095 5022 4998 4993>,
			<5500 5222 5097 5024 5000 4994>,
			<5503 5227 5101 5026 5001 4995>,
			<5505 5232 5105 5029 5003 4997>,
			<5501 5239 5114 5034 5005 4998>,
			<5488 5245 5121 5039 5008 5000>,
			<5473 5243 5122 5045 5013 5004>,
			<5453 5224 5120 5054 5021 5011>,
			<5434 5205 5117 5057 5024 5014>,
			<5424 5191 5099 5042 5015 5006>,
			<5418 5180 5077 5022 5001 4994>,
			<5411 5174 5070 5014 4995 4989>,
			<5404 5170 5067 5010 4990 4986>,
			<5398 5168 5066 5008 4989 4984>,
			<5393 5168 5066 5009 4989 4984>,
			<5389 5168 5067 5010 4989 4984>,
			<5387 5168 5068 5012 4990 4985>,
			<5395 5168 5070 5014 4992 4986>,
			<5409 5167 5072 5017 4995 4989>,
			<5425 5165 5073 5019 4999 4992>,
			<5448 5163 5074 5021 5002 4995>,
			<5473 5164 5075 5024 5003 4997>,
			<5500 5176 5076 5027 5005 4999>,
			<5531 5191 5077 5029 5005 5000>,
			<5562 5209 5080 5025 5000 4995>,
			<5595 5230 5084 5020 4996 4989>,
			<5628 5249 5088 5018 4996 4991>,
			<5662 5269 5092 5018 4998 4998>,
			<5697 5288 5097 5018 5000 5000>,
			<5737 5306 5102 5021 5001 5000>,
			<5783 5326 5109 5023 5000 4998>,
			<5838 5350 5116 5017 4988 4984>,
			<5907 5387 5128 5020 4990 4987>,
			<6006 5424 5133 5027 5007 5007>,
			<6037 5464 5149 5037 5019 5020>,
			<6117 5520 5170 5049 5031 5032>,
			<6243 5596 5198 5060 5037 5034>,
			<6446 5713 5224 5050 5018 5013>,
			<6944 5941 5254 5035 5005 5001>,
			<8539 6803 5338 5037 5006 5003>,
			<13216 11100 5654 5047 5010 5007>,
			<31874 33710 7925 5066 5024 5022>,
			<31874 33710 7925 5066 5024 5022>,
			<31874 33710 7925 5066 5024 5022>;
	};

};
